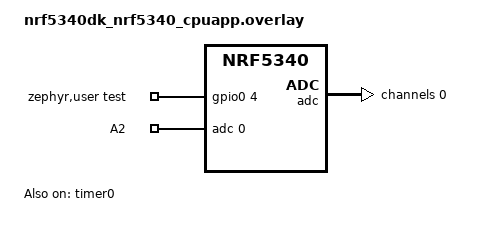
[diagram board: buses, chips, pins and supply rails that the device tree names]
/*
 * Copyright (c) 2025 Nordic Semiconductor ASA
 *
 * SPDX-License-Identifier: LicenseRef-Nordic-5-Clause
 */

/*
 * Required loopbacks:
 * P0.0.5 (AIN1) <-> P0.04
 */

/ {
	aliases {
		tst-timer = &timer0;
	};

	zephyr,user {
		test-gpios = <&gpio0 4 GPIO_ACTIVE_HIGH>;
		io-channels = <&adc 0>;
		io-channel-names = "A2";
	};
};

dut_adc: &adc {
	#address-cells = <1>;
	#size-cells = <0>;

	channel@0 {
		reg = <0>;
		zephyr,gain = "ADC_GAIN_1";
		zephyr,reference = "ADC_REF_INTERNAL";
		zephyr,acquisition-time = <ADC_ACQ_TIME_DEFAULT>;
		zephyr,input-positive = <NRF_SAADC_AIN1>;
	};
};

&gpio0 {
	status = "okay";
};

&timer0 {
	status = "okay";
};
